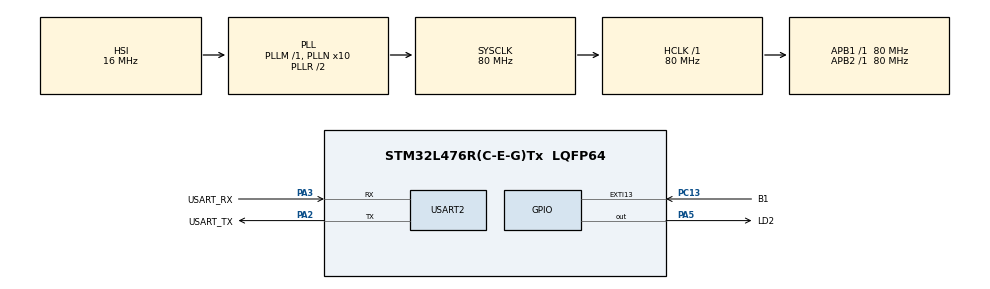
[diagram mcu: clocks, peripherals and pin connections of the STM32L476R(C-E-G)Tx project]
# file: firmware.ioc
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FREERTOS.Tasks01=defaultTask,24,128,StartDefaultTask,Default,NULL,Dynamic,NULL,NULL
FREERTOS.configCHECK_FOR_STACK_OVERFLOW=2
FREERTOS.configTOTAL_HEAP_SIZE=32768
FREERTOS.configUSE_MALLOC_FAILED_HOOK=1
FREERTOS.configUSE_NEWLIB_REENTRANT=1
Mcu.Family=STM32L4
Mcu.Name=STM32L476R(C-E-G)Tx
Mcu.Package=LQFP64
NVIC.EXTI15_10_IRQn=true\:5\:0\:false\:false\:true\:true\:true\:true\:true
NVIC.PriorityGroup=NVIC_PRIORITYGROUP_4
NVIC.TIM6_DAC_IRQn=true\:15\:0\:false\:false\:true\:false\:false\:true\:true
NVIC.TimeBase=TIM6_DAC_IRQn
NVIC.TimeBaseIP=TIM6
NVIC.USART2_IRQn=true\:6\:0\:true\:false\:true\:true\:true\:true\:true
PA13\ (JTMS-SWDIO).GPIO_Label=TMS
PA13\ (JTMS-SWDIO).Mode=Serial_Wire
PA13\ (JTMS-SWDIO).Signal=SYS_JTMS-SWDIO
PA14\ (JTCK-SWCLK).GPIO_Label=TCK
PA14\ (JTCK-SWCLK).Mode=Serial_Wire
PA14\ (JTCK-SWCLK).Signal=SYS_JTCK-SWCLK
PA2.GPIO_Label=USART_TX
PA2.GPIO_Mode=GPIO_MODE_AF_PP
PA2.GPIO_PuPd=GPIO_NOPULL
PA2.GPIO_Speed=GPIO_SPEED_FREQ_VERY_HIGH
PA2.Mode=Asynchronous
PA2.Signal=USART2_TX
PA3.GPIO_Label=USART_RX
PA3.GPIO_Mode=GPIO_MODE_AF_PP
PA3.GPIO_PuPd=GPIO_NOPULL
PA3.GPIO_Speed=GPIO_SPEED_FREQ_VERY_HIGH
PA3.Mode=Asynchronous
PA3.Signal=USART2_RX
PA5.GPIO_Label=LD2
PA5.Signal=GPIO_Output
PB3\ (JTDO-TRACESWO).GPIO_Label=SWO
PB3\ (JTDO-TRACESWO).Signal=SYS_JTDO-SWO
PC13.GPIO_Label=B1
PC13.GPIO_ModeDefaultEXTI=GPIO_MODE_IT_FALLING
PC13.GPIO_PuPd=GPIO_PULLUP
PC13.Signal=GPXTI13
PC14-OSC32_IN\ (PC14).Signal=RCC_OSC32_IN
PC15-OSC32_OUT\ (PC15).Signal=RCC_OSC32_OUT
PH0-OSC_IN\ (PH0).Signal=RCC_OSC_IN
PH1-OSC_OUT\ (PH1).Signal=RCC_OSC_OUT
ProjectManager.HeapSize=0x200
ProjectManager.StackSize=0x400
ProjectManager.TargetToolchain=STM32CubeIDE
RCC.ADCFreq_Value=64000000
RCC.AHBFreq_Value=80000000
RCC.APB1Freq_Value=80000000
RCC.APB1TimFreq_Value=80000000
RCC.APB2Freq_Value=80000000
RCC.APB2TimFreq_Value=80000000
RCC.CortexFreq_Value=80000000
RCC.HCLKFreq_Value=80000000
RCC.HSE_VALUE=8000000
RCC.HSI_VALUE=16000000
RCC.LSE_VALUE=32768
RCC.MSI_VALUE=4000000
RCC.PLLN=10
RCC.PLLSourceVirtual=RCC_PLLSOURCE_HSI
RCC.PREFETCH_ENABLE=1
RCC.SYSCLKFreq_VALUE=80000000
RCC.SYSCLKSource=RCC_SYSCLKSOURCE_PLLCLK
RCC.USBFreq_Value=64000000
RCC.VCOOutputFreq_Value=160000000
TIM2.Prescaler=79
USART2.VirtualMode-Asynchronous=VM_ASYNC
VP_FREERTOS_VS_CMSIS_V2.Mode=CMSIS_V2
VP_NUCLEO-L476RG_VS_BSP_COMMON.Mode=COMMON
VP_SYS_VS_tim6.Mode=TIM6
VP_TIM2_VS_ClockSourceINT.Mode=Internal
board=NUCLEO-L476RG

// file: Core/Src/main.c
/* USER CODE BEGIN Header */
/**
  ******************************************************************************
  * @file           : main.c
  * @brief          : Main program body
  ******************************************************************************
  * @attention
  *
  * Copyright (c) 2026 STMicroelectronics.
  * All rights reserved.
  *
  * This software is licensed under terms that can be found in the LICENSE file
  * in the root directory of this software component.
  * If no LICENSE file comes with this software, it is provided AS-IS.
  *
  ******************************************************************************
  */
/* USER CODE END Header */
#include "main.h"
#include "cmsis_os.h"
#include "tim.h"
#include "usart.h"
#include "gpio.h"

void SystemClock_Config(void);
void MX_FREERTOS_Init(void);

int main(void)
{

  /* MCU Configuration--------------------------------------------------------*/

  /* Reset of all peripherals, Initializes the Flash interface and the Systick. */
  HAL_Init();

  /* Configure the system clock */
  SystemClock_Config();

  /* Initialize all configured peripherals */
  MX_GPIO_Init();
  MX_TIM2_Init();
  MX_USART2_UART_Init();

  /* Init scheduler */
  osKernelInitialize();  /* Call init function for freertos objects (in cmsis_os2.c) */
  MX_FREERTOS_Init();

  /* Start scheduler */
  osKernelStart();

  /* We should never get here as control is now taken by the scheduler */

  /* Infinite loop */
  while (1)
  {

  }
}

void SystemClock_Config(void)
{
  RCC_OscInitTypeDef RCC_OscInitStruct = {0};
  RCC_ClkInitTypeDef RCC_ClkInitStruct = {0};

  /** Configure the main internal regulator output voltage
  */
  if (HAL_PWREx_ControlVoltageScaling(PWR_REGULATOR_VOLTAGE_SCALE1) != HAL_OK)
  {
    Error_Handler();
  }

  /** Initializes the RCC Oscillators according to the specified parameters
  * in the RCC_OscInitTypeDef structure.
  */
  RCC_OscInitStruct.OscillatorType = RCC_OSCILLATORTYPE_HSI;
  RCC_OscInitStruct.HSIState = RCC_HSI_ON;
  RCC_OscInitStruct.HSICalibrationValue = RCC_HSICALIBRATION_DEFAULT;
  RCC_OscInitStruct.PLL.PLLState = RCC_PLL_ON;
  RCC_OscInitStruct.PLL.PLLSource = RCC_PLLSOURCE_HSI;
  RCC_OscInitStruct.PLL.PLLM = 1;
  RCC_OscInitStruct.PLL.PLLN = 10;
  RCC_OscInitStruct.PLL.PLLP = RCC_PLLP_DIV7;
  RCC_OscInitStruct.PLL.PLLQ = RCC_PLLQ_DIV2;
  RCC_OscInitStruct.PLL.PLLR = RCC_PLLR_DIV2;
  if (HAL_RCC_OscConfig(&RCC_OscInitStruct) != HAL_OK)
  {
    Error_Handler();
  }

  /** Initializes the CPU, AHB and APB buses clocks
  */
  RCC_ClkInitStruct.ClockType = RCC_CLOCKTYPE_HCLK|RCC_CLOCKTYPE_SYSCLK
                              |RCC_CLOCKTYPE_PCLK1|RCC_CLOCKTYPE_PCLK2;
  RCC_ClkInitStruct.SYSCLKSource = RCC_SYSCLKSOURCE_PLLCLK;
  RCC_ClkInitStruct.AHBCLKDivider = RCC_SYSCLK_DIV1;
  RCC_ClkInitStruct.APB1CLKDivider = RCC_HCLK_DIV1;
  RCC_ClkInitStruct.APB2CLKDivider = RCC_HCLK_DIV1;

  if (HAL_RCC_ClockConfig(&RCC_ClkInitStruct, FLASH_LATENCY_4) != HAL_OK)
  {
    Error_Handler();
  }
}

void HAL_TIM_PeriodElapsedCallback(TIM_HandleTypeDef *htim)
{
  if (htim->Instance == TIM6)
  {
    HAL_IncTick();
  }
}

void Error_Handler(void)
{
  /* USER CODE BEGIN Error_Handler_Debug */
  /* User can add his own implementation to report the HAL error return state */
  __disable_irq();
  HAL_GPIO_WritePin(LD2_GPIO_Port, LD2_Pin, GPIO_PIN_SET);   /* solid LD2 = fatal error */
  while (1)
  {
  }
  /* USER CODE END Error_Handler_Debug */
}

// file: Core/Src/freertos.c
/* USER CODE BEGIN Header */
/**
  ******************************************************************************
  * File Name          : freertos.c
  * Description        : Code for freertos applications
  ******************************************************************************
  * @attention
  *
  * Copyright (c) 2026 STMicroelectronics.
  * All rights reserved.
  *
  * This software is licensed under terms that can be found in the LICENSE file
  * in the root directory of this software component.
  * If no LICENSE file comes with this software, it is provided AS-IS.
  *
  ******************************************************************************
  */
/* USER CODE END Header */

#include "FreeRTOS.h"
#include "task.h"
#include "main.h"
#include "cmsis_os.h"

/* USER CODE BEGIN Includes */
#include "app_main.h"
/* USER CODE END Includes */

/* Definitions for defaultTask */
osThreadId_t defaultTaskHandle;
const osThreadAttr_t defaultTask_attributes = {
  .name = "defaultTask",
  .stack_size = 128 * 4,
  .priority = (osPriority_t) osPriorityNormal,
};

void StartDefaultTask(void *argument);

void MX_FREERTOS_Init(void); /* (MISRA C 2004 rule 8.1) */

/* Hook prototypes */
void vApplicationStackOverflowHook(xTaskHandle xTask, signed char *pcTaskName);
void vApplicationMallocFailedHook(void);

/* USER CODE BEGIN 4 */
void vApplicationStackOverflowHook(xTaskHandle xTask, signed char *pcTaskName)
{
   /* Run time stack overflow checking is performed if
   configCHECK_FOR_STACK_OVERFLOW is defined to 1 or 2. This hook function is
   called if a stack overflow is detected. */
   (void)xTask;
   (void)pcTaskName;   /* inspect in the debugger to see which task overflowed */
   taskDISABLE_INTERRUPTS();
   HAL_GPIO_WritePin(LD2_GPIO_Port, LD2_Pin, GPIO_PIN_SET);   /* solid LD2 = fatal error */
   for (;;)
   {
   }
}
/* USER CODE END 4 */

/* USER CODE BEGIN 5 */
void vApplicationMallocFailedHook(void)
{
   /* vApplicationMallocFailedHook() will only be called if
   configUSE_MALLOC_FAILED_HOOK is set to 1 in FreeRTOSConfig.h. It is a hook
   function that will get called if a call to pvPortMalloc() fails.
   pvPortMalloc() is called internally by the kernel whenever a task, queue,
   timer or semaphore is created. It is also called by various parts of the
   demo application. If heap_1.c or heap_2.c are used, then the size of the
   heap available to pvPortMalloc() is defined by configTOTAL_HEAP_SIZE in
   FreeRTOSConfig.h, and the xPortGetFreeHeapSize() API function can be used
   to query the size of free heap space that remains (although it does not
   provide information on how the remaining heap might be fragmented). */
   taskDISABLE_INTERRUPTS();
   HAL_GPIO_WritePin(LD2_GPIO_Port, LD2_Pin, GPIO_PIN_SET);   /* solid LD2 = fatal error */
   for (;;)
   {
   }
}
/* USER CODE END 5 */

void MX_FREERTOS_Init(void) {

  /* Create the thread(s) */
  /* creation of defaultTask */
  defaultTaskHandle = osThreadNew(StartDefaultTask, NULL, &defaultTask_attributes);

  /* USER CODE BEGIN RTOS_THREADS */
  app_start();
  /* USER CODE END RTOS_THREADS */

}

void StartDefaultTask(void *argument)
{
  /* USER CODE BEGIN StartDefaultTask */
  /* defaultTask is not part of the application; remove it so it cannot affect measurements */
  (void)argument;
  vTaskDelete(NULL);
  /* Infinite loop */
  for(;;)
  {
    osDelay(1);
  }
  /* USER CODE END StartDefaultTask */
}
